VERSION ""

NS_ :

BS_:
BU_: Dashboard PEI TelemNode Xsens TelemHost
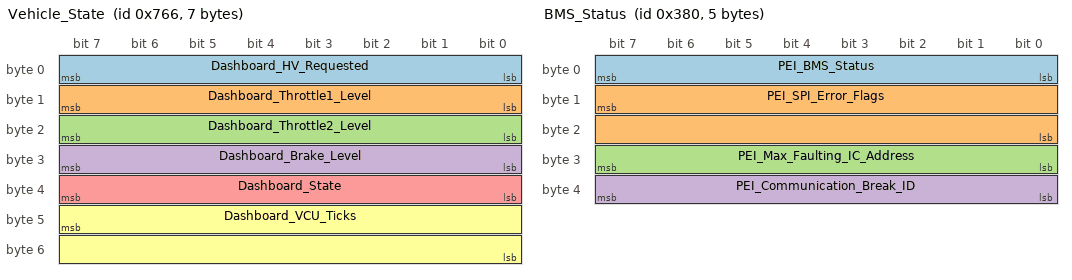
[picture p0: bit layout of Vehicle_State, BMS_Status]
BO_ 1894 Vehicle_State: 7 Dashboard
   SG_ Dashboard_HV_Requested : 7|8@0+ (1,0) [0|1] "" Vector__XXX
   SG_ Dashboard_Throttle1_Level : 15|8@0+ (1,0) [0|100] "%" Vector__XXX
   SG_ Dashboard_Throttle2_Level : 23|8@0+ (1,0) [0|100] "%" Vector__XXX
   SG_ Dashboard_Brake_Level : 31|8@0+ (1,0) [0|100] "%" Vector__XXX
   SG_ Dashboard_State : 39|8@0+ (1,0) [0|255] "" Vector__XXX
   SG_ Dashboard_VCU_Ticks : 47|16@0+ (1,0) [0|65535] "ms" Vector__XXX

BO_ 896 BMS_Status: 5 PEI
   SG_ PEI_BMS_Status : 7|8@0+ (1,0) [0|255] "" Vector__XXX
   SG_ PEI_SPI_Error_Flags : 15|16@0+ (1,0) [0|65535] "" Vector__XXX
   SG_ PEI_Max_Faulting_IC_Address : 31|8@0+ (1,0) [0|9] "" Vector__XXX
   SG_ PEI_Communication_Break_ID : 39|8@0- (1,0) [-1|9] "" Vector__XXX

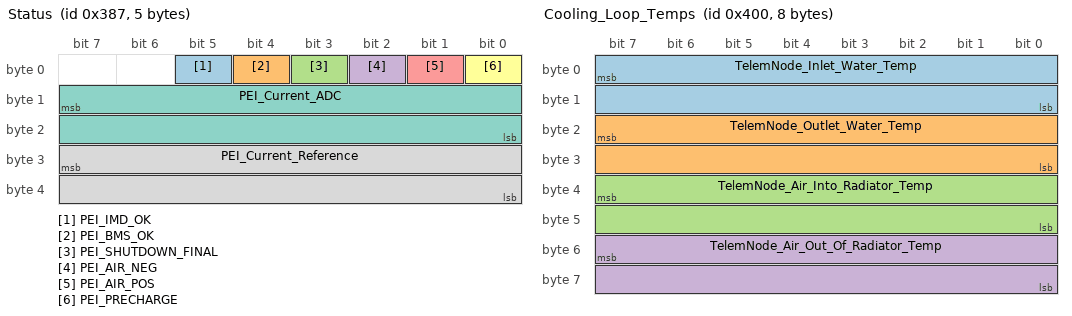
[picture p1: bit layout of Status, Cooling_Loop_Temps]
BO_ 903 Status: 5 PEI
   SG_ PEI_IMD_OK : 5|1@0+ (1,0) [0|1] "" Vector__XXX
   SG_ PEI_BMS_OK : 4|1@0+ (1,0) [0|1] "" Vector__XXX
   SG_ PEI_SHUTDOWN_FINAL : 3|1@0+ (1,0) [0|1] "" Vector__XXX
   SG_ PEI_AIR_NEG : 2|1@0+ (1,0) [0|1] "" Vector__XXX
   SG_ PEI_AIR_POS : 1|1@0+ (1,0) [0|1] "" Vector__XXX
   SG_ PEI_PRECHARGE : 0|1@0+ (1,0) [0|1] "" Vector__XXX
   SG_ PEI_Current_ADC : 15|16@0+ (1,0) [0|65535] "Raw_ADC" Vector__XXX
   SG_ PEI_Current_Reference : 31|16@0- (1,0) [-2048|2047] "Raw_ADC" Vector__XXX

BO_ 1024 Cooling_Loop_Temps: 8 TelemNode
   SG_ TelemNode_Inlet_Water_Temp : 7|16@0- (0.1,0) [-3276.8|3276.7] "C" Vector__XXX
   SG_ TelemNode_Outlet_Water_Temp : 23|16@0- (0.1,0) [-3276.8|3276.7] "C" Vector__XXX
   SG_ TelemNode_Air_Into_Radiator_Temp : 39|16@0- (0.1,0) [-3276.8|3276.7] "C" Vector__XXX
   SG_ TelemNode_Air_Out_Of_Radiator_Temp : 55|16@0- (0.1,0) [-3276.8|3276.7] "C" Vector__XXX

BO_ 1026 Cool_Loop_Pressures: 4 TelemNode
   SG_ TelemNode_Inlet_Water_Pressure : 7|16@0+ (0.01,0) [0|1] "PSI" Vector__XXX
   SG_ TelemNode_Outlet_Water_Pressure : 23|16@0+ (0.01,0) [0|1] "PSI" Vector__XXX

BO_ 1025 Wheel_Speed_Rear: 4 TelemNode
   SG_ TelemNode_Wheel_Speed_Rear_Right : 7|16@0+ (1,0) [0|65535] "CPS/RPM" Vector__XXX
   SG_ TelemNode_Wheel_Speed_Rear_Left : 23|16@0+ (1,0) [0|65535] "CPS/RPM" Vector__XXX

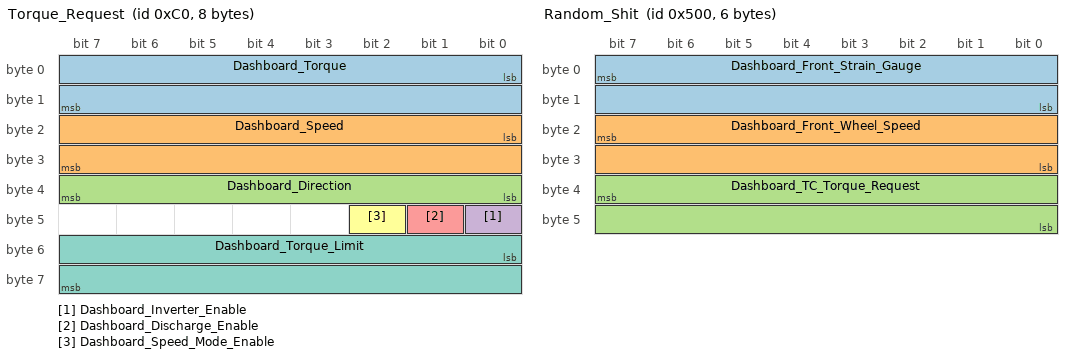
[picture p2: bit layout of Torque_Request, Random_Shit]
BO_ 192 Torque_Request: 8 Dashboard
   SG_ Dashboard_Torque : 0|16@1- (0.1,0) [-3276.8|3276.7] "Nm" Vector__XXX
   SG_ Dashboard_Speed : 16|16@1+ (1,0) [0|65535] "RPM" Vector__XXX
   SG_ Dashboard_Direction : 32|8@1+ (1,0) [0|1] "" Vector__XXX
   SG_ Dashboard_Inverter_Enable : 40|1@1+ (1,0) [0|1] "" Vector__XXX
   SG_ Dashboard_Discharge_Enable : 41|1@1+ (1,0) [0|1] "" Vector__XXX
   SG_ Dashboard_Speed_Mode_Enable : 42|1@1+ (1,0) [0|1] "" Vector__XXX
   SG_ Dashboard_Torque_Limit : 48|16@1+ (0.1,0) [0|6553.5] "Nm" Vector__XXX

BO_ 1280 Random_Shit: 6 Dashboard
   SG_ Dashboard_Front_Strain_Gauge : 7|16@0+ (1,0) [0|65535] "" Vector__XXX
   SG_ Dashboard_Front_Wheel_Speed : 23|16@0+ (1,0) [0|65535] "RPM" Vector__XXX
   SG_ Dashboard_TC_Torque_Request : 39|16@0+ (0.1,0) [0|6553.5] "Nm" Vector__XXX

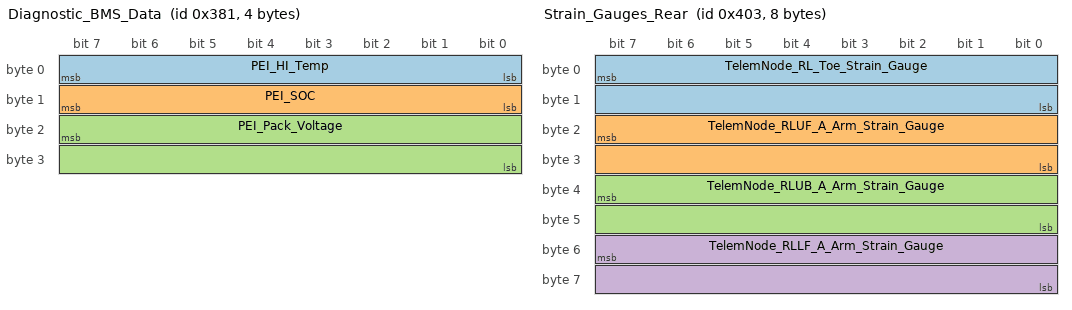
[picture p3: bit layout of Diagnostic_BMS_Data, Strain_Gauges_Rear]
BO_ 897 Diagnostic_BMS_Data: 4 PEI
   SG_ PEI_HI_Temp : 7|8@0+ (1,0) [0|255] "C" Vector__XXX
   SG_ PEI_SOC : 15|8@0+ (1,0) [0|100] "%" Vector__XXX
   SG_ PEI_Pack_Voltage : 23|16@0- (1,0) [-32768|32767] "V" Vector__XXX

BO_ 1027 Strain_Gauges_Rear: 8 TelemNode
   SG_ TelemNode_RL_Toe_Strain_Gauge : 7|16@0+ (1,0) [0|65535] "" Vector__XXX
   SG_ TelemNode_RLUF_A_Arm_Strain_Gauge : 23|16@0+ (1,0) [0|65535] "" Vector__XXX
   SG_ TelemNode_RLUB_A_Arm_Strain_Gauge : 39|16@0+ (1,0) [0|65535] "" Vector__XXX
   SG_ TelemNode_RLLF_A_Arm_Strain_Gauge : 55|16@0+ (1,0) [0|65535] "" Vector__XXX

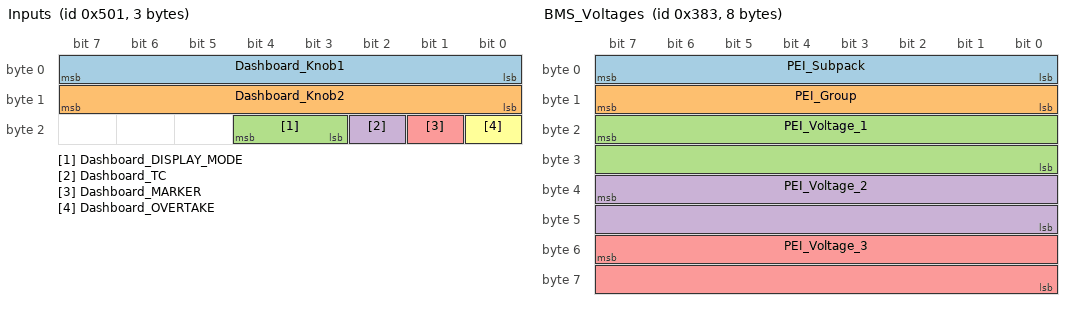
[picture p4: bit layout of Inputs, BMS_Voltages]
BO_ 1281 Inputs: 3 Dashboard
   SG_ Dashboard_Knob1 : 7|8@0+ (1,0) [0|100] "" Vector__XXX
   SG_ Dashboard_Knob2 : 15|8@0+ (1,0) [0|100] "" Vector__XXX
   SG_ Dashboard_DISPLAY_MODE : 20|2@0+ (1,0) [0|1] "" Vector__XXX
   SG_ Dashboard_TC : 18|1@0+ (1,0) [0|1] "" Vector__XXX
   SG_ Dashboard_MARKER : 17|1@0+ (1,0) [0|1] "" Vector__XXX
   SG_ Dashboard_OVERTAKE : 16|1@0+ (1,0) [0|1] "" Vector__XXX

BO_ 904 Current: 4 PEI
   SG_ PEI_Current : 7|16@0- (0.01,0) [-327.68|327.67] "A" Vector__XXX

BO_ 898 High_Level_BMS_Data: 4 PEI
   SG_ PEI_HI_Temp : 7|16@0+ (0.001,0) [0|65.535] "C" Vector__XXX
   SG_ PEI_Pack_Voltage : 23|16@0+ (0.01,0) [0|655.35] "V" Vector__XXX

BO_ 899 BMS_Voltages: 8 PEI
   SG_ PEI_Subpack : 7|8@0+ (1,0) [0|4] "" Vector__XXX
   SG_ PEI_Group : 15|8@0+ (1,0) [0|7] "" Vector__XXX
   SG_ PEI_Voltage_1 : 23|16@0+ (0.01,0) [0|655.35] "V" Vector__XXX
   SG_ PEI_Voltage_2 : 39|16@0+ (0.01,0) [0|655.35] "V" Vector__XXX
   SG_ PEI_Voltage_3 : 55|16@0+ (0.01,0) [0|655.35] "V" Vector__XXX

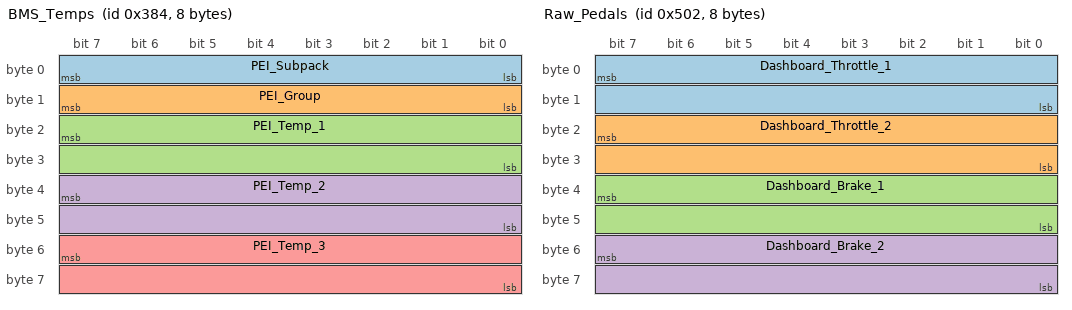
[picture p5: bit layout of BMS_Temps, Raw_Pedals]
BO_ 900 BMS_Temps: 8 PEI
   SG_ PEI_Subpack : 7|8@0+ (1,0) [0|4] "" Vector__XXX
   SG_ PEI_Group : 15|8@0+ (1,0) [0|7] "" Vector__XXX
   SG_ PEI_Temp_1 : 23|16@0+ (0.001,0) [0|65.535] "C" Vector__XXX
   SG_ PEI_Temp_2 : 39|16@0+ (0.001,0) [0|65.535] "C" Vector__XXX
   SG_ PEI_Temp_3 : 55|16@0+ (0.001,0) [0|65.535] "C" Vector__XXX

BO_ 1282 Raw_Pedals: 8 Dashboard
   SG_ Dashboard_Throttle_1 : 7|16@0+ (1,0) [0|65535] "" Vector__XXX
   SG_ Dashboard_Throttle_2 : 23|16@0+ (1,0) [0|65535] "" Vector__XXX
   SG_ Dashboard_Brake_1 : 39|16@0+ (1,0) [0|65535] "" Vector__XXX
   SG_ Dashboard_Brake_2 : 55|16@0+ (1,0) [0|65535] "" Vector__XXX

BO_ 1283 MCAC_Power: 8 Dashboard
   SG_ Motor_Power : 7|32@0- (1,0) [-200000|200000] "Watts" Vector__XXX
   SG_ Acc_Power : 39|32@0- (1,0) [-200000|200000] "Watts" Vector__XXX

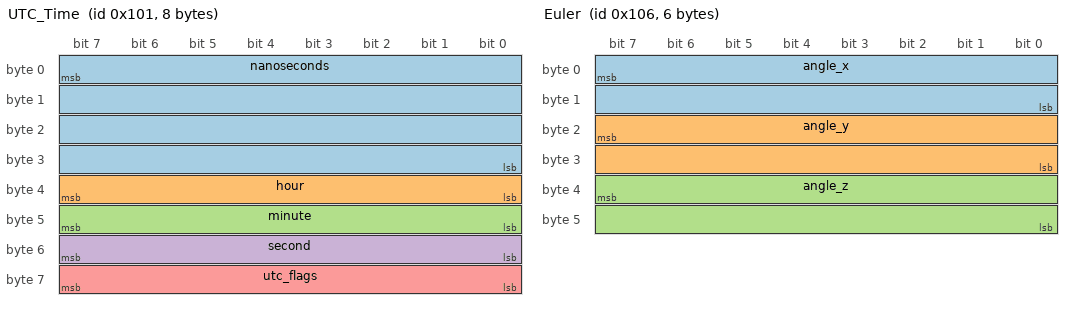
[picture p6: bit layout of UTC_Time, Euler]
BO_ 257 UTC_Time: 8 Xsens
   SG_ nanoseconds : 7|32@0+ (1,0) [0|4.29497e+09] "ns" Vector__XXX
   SG_ hour : 39|8@0+ (1,0) [0|24] "hour" Vector__XXX
   SG_ minute : 47|8@0+ (1,0) [0|60] "" Vector__XXX
   SG_ second : 55|8@0+ (1,0) [0|60] "" Vector__XXX
   SG_ utc_flags : 63|8@0+ (1,0) [0|255] "" Vector__XXX

BO_ 258 Packet_Count: 2 Xsens
   SG_ packet_count : 7|16@0+ (1,0) [0|65535] "" Vector__XXX

BO_ 262 Euler: 6 Xsens
   SG_ angle_x : 7|16@0- (0.01,0) [-100000|100000] "" Vector__XXX
   SG_ angle_y : 23|16@0- (0.01,0) [-100000|100000] "" Vector__XXX
   SG_ angle_z : 39|16@0- (0.01,0) [-100000|100000] "" Vector__XXX

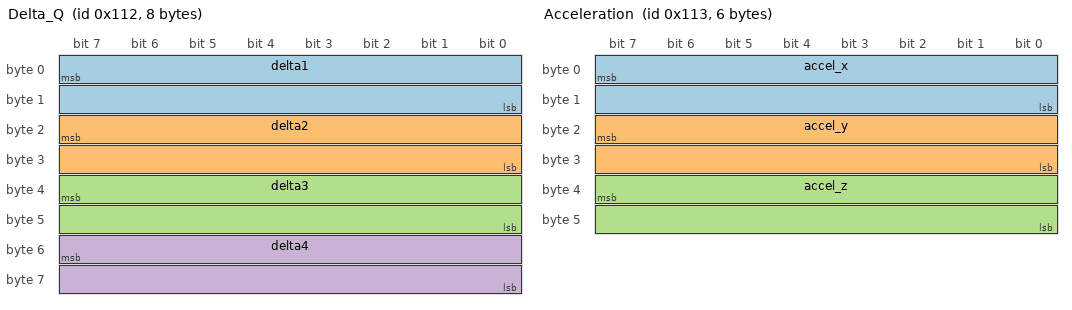
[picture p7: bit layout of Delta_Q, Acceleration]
BO_ 274 Delta_Q: 8 Xsens
   SG_ delta1 : 7|16@0- (0.01,0) [-100000|100000] "" Vector__XXX
   SG_ delta2 : 23|16@0- (0.01,0) [-100000|100000] "" Vector__XXX
   SG_ delta3 : 39|16@0- (0.01,0) [-100000|100000] "" Vector__XXX
   SG_ delta4 : 55|16@0+ (0.01,0) [-100000|100000] "" Vector__XXX

BO_ 295 Lat_Lon: 8 Xsens
   SG_ latitude : 7|32@0- (0.0001,0) [-1e+07|1e+07] "degrees" Vector__XXX
   SG_ longitude : 39|32@0- (0.0001,0) [-1e+07|1e+07] "degrees" Vector__XXX

BO_ 275 Acceleration: 6 Xsens
   SG_ accel_x : 7|16@0- (0.01,0) [-100000|100000] "m/s^2" Vector__XXX
   SG_ accel_y : 23|16@0- (0.01,0) [-100000|100000] "m/s^2" Vector__XXX
   SG_ accel_z : 39|16@0- (0.01,0) [-100000|100000] "m/s^2" Vector__XXX

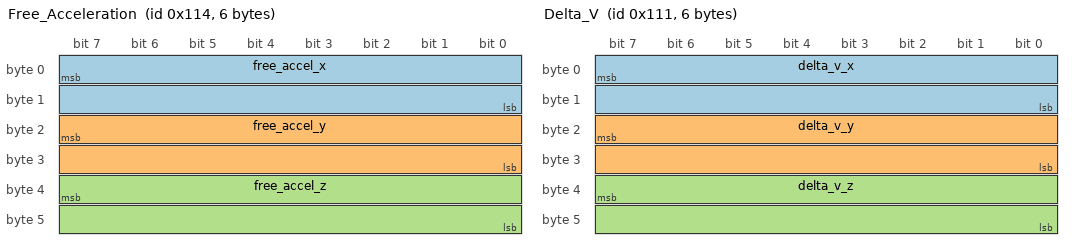
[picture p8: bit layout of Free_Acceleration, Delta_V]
BO_ 276 Free_Acceleration: 6 Xsens
   SG_ free_accel_x : 7|16@0- (0.01,0) [-100000|100000] "m/s^2" Vector__XXX
   SG_ free_accel_y : 23|16@0- (0.01,0) [-100000|100000] "m/s^2" Vector__XXX
   SG_ free_accel_z : 39|16@0- (0.01,0) [-100000|100000] "m/s^2" Vector__XXX

BO_ 273 Delta_V: 6 Xsens
   SG_ delta_v_x : 7|16@0- (0.01,0) [-100000|100000] "m/s" Vector__XXX
   SG_ delta_v_y : 23|16@0- (0.01,0) [-100000|100000] "m/s" Vector__XXX
   SG_ delta_v_z : 39|16@0- (0.01,0) [-100000|100000] "m/s" Vector__XXX

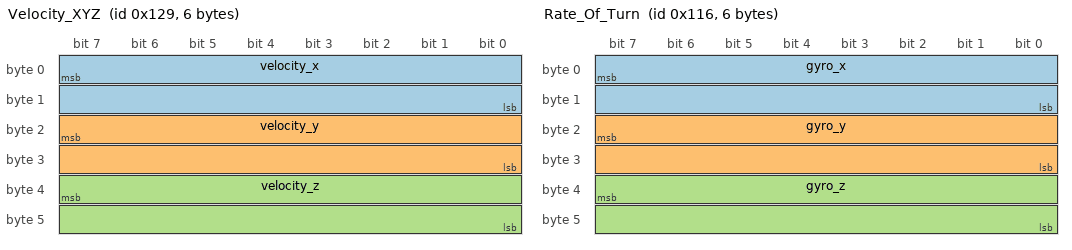
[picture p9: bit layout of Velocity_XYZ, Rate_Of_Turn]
BO_ 297 Velocity_XYZ: 6 Xsens
   SG_ velocity_x : 7|16@0- (0.01,0) [-100000|100000] "m/s" Vector__XXX
   SG_ velocity_y : 23|16@0- (0.01,0) [-100000|100000] "m/s" Vector__XXX
   SG_ velocity_z : 39|16@0- (0.01,0) [-100000|100000] "m/s" Vector__XXX

BO_ 278 Rate_Of_Turn: 6 Xsens
   SG_ gyro_x : 7|16@0- (0.01,0) [-100000|100000] "rad/s" Vector__XXX
   SG_ gyro_y : 23|16@0- (0.01,0) [-100000|100000] "rad/s" Vector__XXX
   SG_ gyro_z : 39|16@0- (0.01,0) [-100000|100000] "rad/s" Vector__XXX

BO_ 272 Pressure: 4 Xsens
   SG_ pressure : 7|32@0+ (1,0) [0|1e+07] "pascals" Vector__XXX

BO_ 291 StatusWord: 4 Xsens
   SG_ status : 7|32@0+ (1,0) [0|1] "" Vector__XXX

BO_ 1124 Shock_Angles_Front: 4 TelemNode
   SG_ Front_Shock_Angle_1 : 7|16@0+ (1,0) [0|65535] "" Vector__XXX
   SG_ Front_Shock_Angle_2 : 23|16@0+ (1,0) [0|65535] "" Vector__XXX

BO_ 1125 Shock_Angles_Rear: 4 TelemNode
   SG_ Rear_Shock_Angle_1 : 7|16@0+ (1,0) [0|65535] "" Vector__XXX
   SG_ Rear_Shock_Angle_2 : 23|16@0+ (1,0) [0|65535] "" Vector__XXX

BO_ 1120 Wheel_Speeds_Front: 4 TelemNode
   SG_ Front_Wheel_Speed_1 : 7|16@0+ (1,0) [0|65535] "cps" Vector__XXX
   SG_ Front_Wheel_Speed_2 : 23|16@0+ (1,0) [0|65535] "cps" Vector__XXX

BO_ 1121 Wheel_Speeds_Rear: 4 TelemNode
   SG_ Rear_Wheel_Speed_1 : 7|16@0+ (1,0) [0|65535] "cps" Vector__XXX
   SG_ Rear_Wheel_Speed_2 : 23|16@0+ (1,0) [0|65535] "cps" Vector__XXX

BO_ 1129 Brake_Temp: 2 TelemNode
   SG_ Brake_Temp : 7|16@0+ (1,0) [0|65535] "" Vector__XXX

BO_ 1152 Latitude_Longitude: 8 TelemHost
   SG_ Latitude : 7|32@0- (1e-06,0) [-2.14748e+09|2.14748e+09] "degrees" Vector__XXX
   SG_ Longitude : 39|32@0- (1e-06,0) [-2.14748e+09|2.14748e+09] "degrees" Vector__XXX

BA_DEF_ BO_ "GenMsgBackgroundColor" STRING ;
BA_DEF_ BO_ "GenMsgForegroundColor" STRING ;
BA_DEF_ "BusType" STRING ;
BA_DEF_DEF_ "GenMsgBackgroundColor" "#ffffff";
BA_DEF_DEF_ "GenMsgForegroundColor" "#000000";
BA_DEF_DEF_ "BusType" "CAN";

    0 "LV"
    1 "PRECHARGE"
    2 "HV ENABLED"
    3 "DRIVE"
    5 "STARTUP"
    129 "DRV FRM LV"
    130 "PRE TM OUT"
    131 "BR NOT PRS"
    132 "HV OFF DRV"
    133 "SNSR DSCRP"
    134 "BSPD TRIPD"
    135 "SHTDWN OPN"
    136 "UNCALIBRTD"
    137 "HARD BSPD"
    138 "MC FAULT";

    0 "NO ERROR"
    1 "CHARGE MODE"
    2 "BMS TEMP OVER"
    4 "BMS TEMP UNDER"
    8 "OVERVOLT"
    16 "UNDERVOLT"
    32 "OPEN WIRE"
    64 "MISMATCH"
    128 "SPI FAULT";

    0 "A"
    1 "B"
    2 "C"
    3 "D"
    4 "E"
    5 "F"
    6 "G"
    7 "H";
CM_ BU_ Xsens "not actual CAN messages, only used for SD card parsing";
